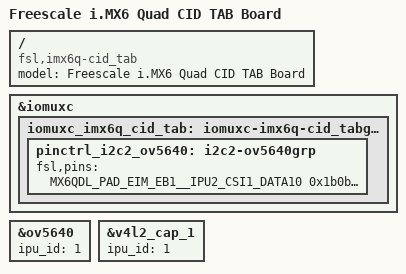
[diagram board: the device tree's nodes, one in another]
/*
 * Copyright 2017 Boundary Devices
 *
 * The code contained herein is licensed under the GNU General Public
 * License. You may obtain a copy of the GNU General Public License
 * Version 2 or later at the following locations:
 *
 * http://www.opensource.org/licenses/gpl-license.html
 * http://www.gnu.org/copyleft/gpl.html
 */

/dts-v1/;

#include <dt-bindings/interrupt-controller/irq.h>
#include "imx6q.dtsi"

&iomuxc {
	iomuxc_imx6q_cid_tab: iomuxc-imx6q-cid_tabgrp {
	};
};

&iomuxc_imx6q_cid_tab {
	pinctrl_i2c2_ov5640: i2c2-ov5640grp {
		fsl,pins = <
			MX6QDL_PAD_EIM_EB1__IPU2_CSI1_DATA10		0x1b0b0
			MX6QDL_PAD_EIM_EB0__IPU2_CSI1_DATA11		0x1b0b0
			MX6QDL_PAD_EIM_A17__IPU2_CSI1_DATA12		0x1b0b0
			MX6QDL_PAD_EIM_A18__IPU2_CSI1_DATA13		0x1b0b0
			MX6QDL_PAD_EIM_A19__IPU2_CSI1_DATA14		0x1b0b0
			MX6QDL_PAD_EIM_A20__IPU2_CSI1_DATA15		0x1b0b0
			MX6QDL_PAD_EIM_A21__IPU2_CSI1_DATA16		0x1b0b0
			MX6QDL_PAD_EIM_A22__IPU2_CSI1_DATA17		0x1b0b0
			MX6QDL_PAD_EIM_A23__IPU2_CSI1_DATA18		0x1b0b0
			MX6QDL_PAD_EIM_A24__IPU2_CSI1_DATA19		0x1b0b0
			MX6QDL_PAD_EIM_DA10__IPU2_CSI1_DATA_EN		0x1b0b0
			MX6QDL_PAD_EIM_A16__IPU2_CSI1_PIXCLK		0x1b0b0
			MX6QDL_PAD_EIM_DA11__IPU2_CSI1_HSYNC		0x1b0b0
			MX6QDL_PAD_EIM_DA12__IPU2_CSI1_VSYNC		0x1b0b0
/* Also used with ov5640 mipi */
/*			MX6QDL_PAD_GPIO_3__CCM_CLKO2			0x000b0 */
#define GP_OV5640_STROBE	<&gpio2 23 GPIO_ACTIVE_HIGH>
			MX6QDL_PAD_EIM_CS0__GPIO2_IO23			0x030b0
#define GP_OV5640_POWER_DOWN	<&gpio2 24 GPIO_ACTIVE_HIGH>
			MX6QDL_PAD_EIM_CS1__GPIO2_IO24			0x0b0b0
#define GP_OV5640_RESET		<&gpio2 25 GPIO_ACTIVE_LOW>
			MX6QDL_PAD_EIM_OE__GPIO2_IO25			0x030b0
		>;
	};
};

#include "imx6qdl-cid_tab.dtsi"
/ {
	model = "Freescale i.MX6 Quad CID TAB Board";
	compatible = "fsl,imx6q-cid_tab", "fsl,imx6q";
};

&ov5640 {
	ipu_id = <1>;
};

&v4l2_cap_1 {
	ipu_id = <1>;
};
